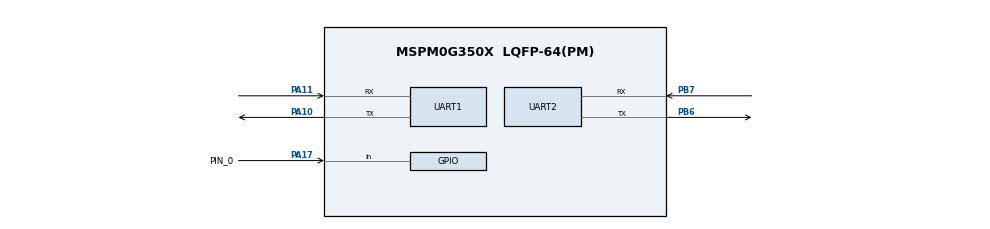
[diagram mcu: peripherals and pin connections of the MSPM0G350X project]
/**
 * @cliArgs --device "MSPM0G350X" --package "LQFP-64(PM)" --part "Default" --product "mspm0_sdk@1.30.00.03"
 * @versions {"tool":"1.19.0+3426"}
 */

/**
 * Import the modules used in this configuration.
 */
const GPIO    = scripting.addModule("/ti/driverlib/GPIO", {}, false);
const GPIO1   = GPIO.addInstance();
const GPIO2   = GPIO.addInstance();
const SYSCTL  = scripting.addModule("/ti/driverlib/SYSCTL");
const SYSTICK = scripting.addModule("/ti/driverlib/SYSTICK");
const UART    = scripting.addModule("/ti/driverlib/UART", {}, false);
const UART1   = UART.addInstance();
const UART2   = UART.addInstance();
const WWDT    = scripting.addModule("/ti/driverlib/WWDT", {}, false);
const WWDT1   = WWDT.addInstance();

/**
 * Write custom configuration values to the imported modules.
 */
const gate7  = system.clockTree["MFCLKGATE"];
gate7.enable = true;

GPIO1.port                               = "PORTA";
GPIO1.$name                              = "LED1";
GPIO1.associatedPins[0].$name            = "PIN_14";
GPIO1.associatedPins[0].internalResistor = "PULL_DOWN";
GPIO1.associatedPins[0].assignedPin      = "14";

const Board = scripting.addModule("/ti/driverlib/Board", {}, false);

GPIO2.$name                              = "MYKEY";
GPIO2.associatedPins[0].$name            = "PIN_0";
GPIO2.associatedPins[0].initialValue     = "SET";
GPIO2.associatedPins[0].direction        = "INPUT";
GPIO2.associatedPins[0].internalResistor = "PULL_UP";
GPIO2.associatedPins[0].assignedPin      = "17";
GPIO2.associatedPins[0].assignedPort     = "PORTA";
GPIO2.associatedPins[0].pin.$assign      = "PA17";

SYSCTL.forceDefaultClkConfig = true;
SYSCTL.clockTreeEn           = true;

SYSTICK.periodEnable      = true;
SYSTICK.systickEnable     = true;
SYSTICK.period            = 32000;
SYSTICK.interruptEnable   = true;
SYSTICK.interruptPriority = "3";

UART1.$name                    = "UART_0";
UART1.uartClkSrc               = "MFCLK";
UART1.enabledInterrupts        = ["RX"];
UART1.targetBaudRate           = 115200;
UART1.peripheral.$assign       = "UART0";
UART1.peripheral.rxPin.$assign = "PA11";
UART1.peripheral.txPin.$assign = "PA10";
UART1.txPinConfig.$name        = "ti_driverlib_gpio_GPIOPinGeneric0";
UART1.rxPinConfig.$name        = "ti_driverlib_gpio_GPIOPinGeneric1";

UART2.$name                             = "UART_1";
UART2.uartClkSrc                        = "MFCLK";
UART2.targetBaudRate                    = 115200;
UART2.enableFIFO                        = true;
UART2.rxFifoThreshold                   = "DL_UART_RX_FIFO_LEVEL_3_4_FULL";
UART2.txFifoThreshold                   = "DL_UART_TX_FIFO_LEVEL_3_4_EMPTY";
UART2.rxTimeoutValue                    = 15;
UART2.enabledInterrupts                 = ["DMA_DONE_RX","RX_TIMEOUT_ERROR"];
UART2.enabledDMARXTriggers              = "DL_UART_DMA_INTERRUPT_RX";
UART2.peripheral.$assign                = "UART1";
UART2.peripheral.rxPin.$assign          = "PB7";
UART2.peripheral.txPin.$assign          = "PB6";
UART2.txPinConfig.$name                 = "ti_driverlib_gpio_GPIOPinGeneric2";
UART2.rxPinConfig.$name                 = "ti_driverlib_gpio_GPIOPinGeneric3";
UART2.DMA_CHANNEL_RX.$name              = "DMA_CH0";
UART2.DMA_CHANNEL_RX.srcLength          = "BYTE";
UART2.DMA_CHANNEL_RX.dstLength          = "BYTE";
UART2.DMA_CHANNEL_RX.transferMode       = "FULL_CH_REPEAT_SINGLE";
UART2.DMA_CHANNEL_RX.addressMode        = "f2b";
UART2.DMA_CHANNEL_RX.peripheral.$assign = "DMA_CH0";

WWDT1.$name        = "WWDT0";
WWDT1.sleepMode    = true;
WWDT1.clockDivider = "8";

/**
 * Pinmux solution for unlocked pins/peripherals. This ensures that minor changes to the automatic solver in a future
 * version of the tool will not impact the pinmux you originally saw.  These lines can be completely deleted in order to
 * re-solve from scratch.
 */
GPIO1.associatedPins[0].pin.$suggestSolution = "PA14";
Board.peripheral.$suggestSolution            = "DEBUGSS";
Board.peripheral.swclkPin.$suggestSolution   = "PA20";
Board.peripheral.swdioPin.$suggestSolution   = "PA19";
WWDT1.peripheral.$suggestSolution            = "WWDT0";
